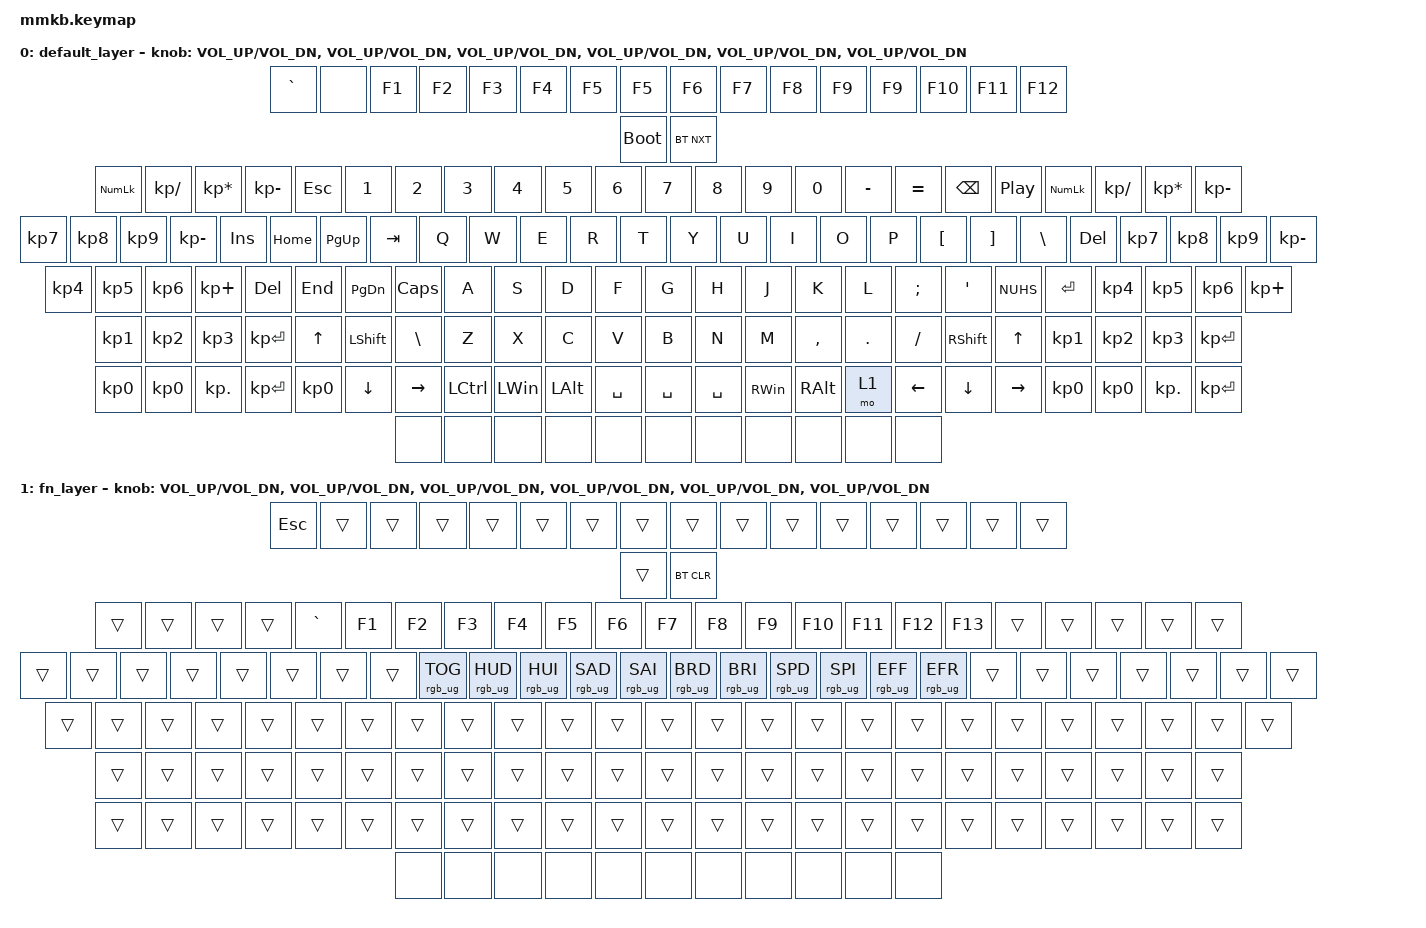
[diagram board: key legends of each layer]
/*
 * copyright (c) 2024 ZMK project contributors
 *
 * SPDX-license-identifier: MIT
 */

#include <behaviors.dtsi>
#include <dt-bindings/zmk/keys.h>
#include <dt-bindings/zmk/bt.h>
#include <dt-bindings/zmk/rgb.h>
#include <dt-bindings/zmk/outputs.h>

// uncomment exactly one layout to use
#define STANDARD           TRUE
// #define STANDARD_F13       TRUE
// #define NAV_KEYS           TRUE
// #define NAV_KEYS_F13       TRUE
// #define FLIPPED_NUMPAD     TRUE
// #define FLIPPED_NUMPAD_F13 TRUE

/ {
    keymap {
        compatible = "zmk,keymap";

        #ifdef STANDARD
        default_layer {
            /*********************************************************************************************************************************************************************************************************************************************************************************************************************************
             * STANDARD LAYOUT (DEFAULT)                                                                                                                                                                                                                                                                                                     *
             * NOTE 1: all the options in the keymap graphic show below are available purely in hardware, with no need to change the keymap (* with some exceptions), just solder the switches to their corresponding mounting point                                                                                                         *
             * NOTE 2: the character / keycode in the middle of the key is the normal binding when pressing it down, the one on the top is for when you hold "SHIFT", and the one on the bottom is when you hold "FN"                                                                                                                        *
             *                                                                                                                                                                                                                                                                                                                               *
             *                                                                                                              *********               *********               *********               *********               *********               *********                                                                                *
             *                                                                                                              * ROTARY*               * ROTARY*               * ROTARY*               * ROTARY*               * ROTARY*               * ROTARY*                                                                                *
             *                                                                                                              *ENCODER*               *ENCODER*               *ENCODER*               *ENCODER*               *ENCODER*               *ENCODER*                                                                                *
             *                                                                                                              *********               *********               *********               *********               *********               *********                                                                                *
             *                                                                                                                                                                                                                                                                                                                               *
             *                                                                                                              *********   *********************************   *********************************   *********************************   *********                                                                                *
             *                                                                                                              *   ~   *   *       *       *       *       *   *       *       *       *       *   *       *       *       *       *   *       *                                                                                *
             *                                                                                                              *   `   *   *  F1   *  F2   *  F3   *  F4   *   *  F5   *  F5   *  F6   *  F7   *   *  F9   *   F9  *  F10  *  F11  *   *  F12  *                                                                                *
             *                                                                                                              ***ESC***   *********************************   *********************************   *********************************   *********                                                                                *
             *                                                                                                               _______         _______________________________         _______________________________         _______________________________                                                                                 *
             *                                                                                                              |   ~   |       |       |       |       |       |       |       |       |       |       |       |       |       |       |       |                                                                                *
             *                                                                                                              |   `   |       |  F1   |  F2   |  F3   |  F4   |       |  F5   |  F6   |  F7   |  F8   |       |  F9   |  F10  |  F11  |  F12  |                                                                                *
             *                                                                                                              |__ESC__|       |_______|_______|_______|_______|       |_______|_______|_______|_______|       |_______|_______|_______|_______|                                                                                *
             *                                                                                                                                                                                                                                                                                                                               *
             *                                                                                                                                                                                                                      *************************                                                                                *
             *                                                                                                                                                                                                                      *   | 1U*BACK 1U* ROTARY*                                                                                *
             *            *********************************                                                                                                                                                                         *   \   *SPACE  *ENCODER*                                   *********************************            *
             *            * ROTARY* ROTARY* ROTARY* ROTARY*                                                                                                                                                                         *************************                                   * ROTARY* ROTARY* ROTARY* ROTARY*            *
             *            *ENCODER*ENCODER*ENCODER*ENCODER*                                                                                                                                                                          _______________________                                    *ENCODER*ENCODER*ENCODER*ENCODER*            *
             *            *********************************                                                                                                                                                                         | FLASH |BT_NEXT| POWER |                                   *********************************            *
             *             _______________________________                                                                   _______________________________________________________________________________________________________|_______|BT_CLR_|_______|                                    _______________________________             *
             *            |  NUM  |       |       |       |                                                                 |       |   !   |   @   |   #   |   $   |   %   |   ^   |   &   |   *   |   (   |   )   |   _   |   +   |               |       |                                   |  NUM  |       |       |       |            *
             *            |  LOCK |   \   |   *   |   -   |                                                                 |  ESC  |   1   |   2   |   3   |   4   |   5   |   6   |   7   |   8   |   9   |   0   |   -   |   =   |   BACKSPACE   |  PLAY |                                   |  LOCK |   \   |   *   |   -   |            *
             *  ********* |_______|_______|_______|_______| *********      _______________________                          |___`___|___F1__|___F2__|___F3__|___F4__|___F5__|___F6__|___F7__|___F8__|___F9__|__F10__|__F11__|__F12__|______F13______|_______|       *************     ********* |_______|_______|_______|_______| *********  *
             *  *     2U* |       |       |       |       | *     1U*     |       |       |       |                         |           |       |       |       |       |       |       |       |       |       |       |   {   |   }   |     |     |       |       *        ISO*     *     2U* |       |       |       |       | *     1U*  *
             *  *       * |   7   |   8   |   9   |       | *   -   *     |  INS  |  HOME | PG UP |                         |    TAB    |   Q   |   W   |   E   |   R   |   T   |   Y   |   U   |   I   |   O   |   P   |   [   |   ]   |     \     |  DEL  |       *           *     *       * |   7   |   8   |   9   |       | *   -   *  *
             *  *   4   * |_______|_______|_______|   +   | *********     |_______|_______|_______|         *************** |___________|RGB_TOG|RGB_HUD|RGB_HUI|RGB_SAD|RGB_SAI|RGB_BRD|RGB_BRI|RGB_SPD|RGB_SPI|RGB_EFF|RGB_EFR|_______|___________|_______| *********  ENTER  *     *   4   * |_______|_______|_______|   +   | *********  *
             *  *       * |       |       |       |       | *     1U*     |       |       |       |         *STEPPED 1.75U* |             |       |       |       |       |       |       |       |       |       |   :   |   "   |                 |       | *   | 1U*         *     *       * |       |       |       |       | *     1U*  *
             *  *       * |   4   |   5   |   6   |       | *   +   *     |  DEL  |  END  | PG DN |         *CAPS LOCK    * |  CAPS LOCK  |   A   |   S   |   D   |   F   |   G   |   H   |   J   |   K   |   L   |   ;   |   '   |      ENTER      |       | *   \   *         *     *       * |   4   |   5   |   6   |       | *   +   *  *
             *  ********* |_______|_______|_______|_______| *********     |_______|_______|_______|     ******************* |_____________|_______|_______|_______|_______|_______|_______|_______|_______|_______|_______|_______|_________________|DISPLAY| *******************     ********* |_______|_______|_______|_______| *********  *
             *  *     2U* |       |       |       |       | *     1U*             |       |             *    1.25U*   | 1U* |                 |       |       |       |       |       |       |       |   <   |   >   |   ?   |             |       |       |                         *     2U* |       |       |       |       | *     1U*  *
             *  *       * |   1   |   2   |   3   |       | * ENTER *             |  UP   |             * L SHIFT *   \   * |     L SHIFT     |   Z   |   X   |   C   |   V   |   B   |   N   |   M   |   ,   |   .   |   /   |   R SHIFT   |  UP   |       |                         *       * |   1   |   2   |   3   |       | * ENTER *  *
             *  *   0   * |_______|_______|_______| ENTER | *********      _______|_______|_______      ******************* |_________________|_______|_______|_______|_______|_______|_______|_______|_______|_______|_______|_____________|_______|_______|                         *   0   * |_______|_______|_______| ENTER | *********  *
             *  *       * |               |       |       | *     1U*     |       |       |       |                         |         |         |         |                                                 |         |         |   |       |       |       |                         *       * |               |       |       | *     1U*  *
             *  *       * |       0       |   .   |       | * ENTER *     |   0   |  DOWN | RIGHT |                         |  L CTRL |  L WIN  |  L ALT  |                                                 |  R ALT  |   FN    |   |  LEFT |  DOWN | RIGHT |                         *       * |       0       |   .   |       | * ENTER *  *
             *  ********* |_______________|_______|_______| *********     |_______|_______|_______|                         |_________|_________|_________|_________________________________________________|_________|_________|   |_______|_______|_______|                         ********* |_______________|_______|_______| *********  *
             *                                                                                                                                                                                                                                                                                                                               *
             *            *********************************                                                                                                                                                                   ***********************                                           *********************************            *
             *            *     1U*     1U*             2U*                                                                                                                                                                   *                2.75U*                                           *     1U*     1U*             2U*            *
             *            *   0   *   0   *     RIGHT     *                                                                                                                                                                   *       R SHIFT       *                                           *   0   *   0   *     RIGHT     *            *
             *            *********************************                                                                 *************************************************************************************************************************                                           *********************************            *
             *                                                                                                              *       1.5U*     1U*       1.5U*                                                     7U*       1.5U*     1U*       1.5U*                                                                                        *
             *                                                                                                              *  L CTRL   * L WIN *   L ALT   *                                                       *   R ALT   * R WIN *  R CTRL   *                                                                                        *
             *                                                                                                              *************************************************************************************************************************                                                                                        *
             *                                                                                                                                                                                                                                                                                                                               *
             *                                                                                                                                            ***************************************************                                                                                                                                *
             *                                                                                                                                            *                2.75U*            2.25U*    1.25U*                                                                                                                                *
             *                                                                                                                                            *                     *                 *  R WIN  *                                                                                                                                *
             *                                                                                                                                            ***************************************************                                                                                                                                *
             *                                                                                                                                                                                                                                                                                                                               *
             *********************************************************************************************************************************************************************************************************************************************************************************************************************************/
            bindings = <
                                                                                                                            &kp GRAVE     &none &kp F1 &kp F2 &kp F3 &kp F4     &kp F5 &kp F5 &kp F6 &kp F7 &kp F8     &kp F9 &kp F9 &kp F10 &kp F11 &kp F12
                                                                                                        
                                                                                                                                                                                                                            &bootloader &bt BT_NXT
                &kp KP_NLCK &kp KP_SLASH &kp KP_MULTIPLY &kp KP_MINUS                                                       &kp ESC &kp N1  &kp N2  &kp N3  &kp N4  &kp N5  &kp N6  &kp N7  &kp N8  &kp N9  &kp N0  &kp MINUS  &kp EQUAL   &kp BSPC  &kp C_PP                         &kp KP_NLCK &kp KP_SLASH &kp KP_MULTIPLY &kp KP_MINUS
                &kp KP_N7   &kp KP_N8    &kp KP_N9       &kp KP_MINUS    &kp INS   &kp HOME &kp PG_UP                       &kp TAB     &kp Q   &kp W   &kp E   &kp R   &kp T   &kp Y   &kp U   &kp I   &kp O   &kp P   &kp LBKT &kp RBKT   &kp BSLH  &kp DEL                         &kp KP_N7   &kp KP_N8    &kp KP_N9       &kp KP_MINUS
                &kp KP_N4   &kp KP_N5    &kp KP_N6       &kp KP_PLUS     &kp DEL   &kp END  &kp PG_DN                       &kp CAPS      &kp A   &kp S   &kp D   &kp F   &kp G   &kp H   &kp J   &kp K   &kp L  &kp SEMI &kp APOS &kp NUHS &kp ENTER                                 &kp KP_N4   &kp KP_N5    &kp KP_N6       &kp KP_PLUS
                &kp KP_N1   &kp KP_N2    &kp KP_N3       &kp KP_ENTER              &kp UP                                   &kp LSHFT &kp BSLH &kp Z  &kp X   &kp C   &kp V   &kp B   &kp N   &kp M   &kp COMMA &kp DOT &kp FSLH    &kp RSHFT  &kp UP                                 &kp KP_N1   &kp KP_N2    &kp KP_N3       &kp KP_ENTER
                &kp KP_N0   &kp KP_N0    &kp KP_DOT      &kp KP_ENTER    &kp KP_N0 &kp DOWN &kp RIGHT                       &kp LCTRL &kp LWIN  &kp LALT  &kp SPACE  &kp SPACE  &kp SPACE         &kp RWIN  &kp RALT  &mo 1       &kp LEFT &kp DOWN &kp RIGHT                         &kp KP_N0   &kp KP_N0    &kp KP_DOT      &kp KP_ENTER

                // unused virtual keys (no mounting points / footprints / traces on board)
                &none &none &none &none &none &none &none &none &none &none &none
            >;

            sensor-bindings = <&inc_dec_kp C_VOL_UP C_VOL_DN &inc_dec_kp C_VOL_UP C_VOL_DN &inc_dec_kp C_VOL_UP C_VOL_DN &inc_dec_kp C_VOL_UP C_VOL_DN &inc_dec_kp C_VOL_UP C_VOL_DN &inc_dec_kp C_VOL_UP C_VOL_DN>;
        };

        fn_layer {
            bindings = <
                                                                                                                            &kp ESC      &trans &trans &trans &trans &trans      &trans &trans &trans &trans &trans      &trans &trans &trans &trans &trans
                                                                                                        
                                                                                                                                                                                                                            &trans      &bt BT_CLR
                &trans      &trans       &trans          &trans                                                             &kp GRAVE &kp F1  &kp F2  &kp F3  &kp F4  &kp F5  &kp F6  &kp F7  &kp F8  &kp F9  &kp F10 &kp F11    &kp F12     &kp F13   &trans                                                                           &trans      &trans       &trans          &trans
                &trans      &trans       &trans          &trans          &trans    &trans   &trans                          &trans &rgb_ug RGB_TOG &rgb_ug RGB_HUD &rgb_ug RGB_HUI &rgb_ug RGB_SAD &rgb_ug RGB_SAI &rgb_ug RGB_BRD &rgb_ug RGB_BRI &rgb_ug RGB_SPD &rgb_ug RGB_SPI &rgb_ug RGB_EFF &rgb_ug RGB_EFR &trans &trans &trans &trans      &trans       &trans          &trans
                &trans      &trans       &trans          &trans          &trans    &trans   &trans                          &trans        &trans  &trans  &trans  &trans  &trans  &trans  &trans  &trans  &trans &trans   &trans   &trans   &trans                                                                                      &trans      &trans       &trans          &trans
                &trans      &trans       &trans          &trans                    &trans                                   &trans    &trans   &trans &trans  &trans  &trans  &trans  &trans  &trans  &trans    &trans  &trans      &trans     &trans                                                                                   &trans      &trans       &trans          &trans
                &trans      &trans       &trans          &trans          &trans    &trans   &trans                          &trans   &trans     &trans    &trans     &trans     &trans            &trans    &trans    &trans      &trans  &trans    &trans                                                                              &trans      &trans       &trans          &trans
                
                // unused virtual keys (no mounting points / footprints / traces on board)
                &none &none &none &none &none &none &none &none &none &none &none
            >;

            sensor-bindings = <&inc_dec_kp C_VOL_UP C_VOL_DN &inc_dec_kp C_VOL_UP C_VOL_DN &inc_dec_kp C_VOL_UP C_VOL_DN &inc_dec_kp C_VOL_UP C_VOL_DN &inc_dec_kp C_VOL_UP C_VOL_DN &inc_dec_kp C_VOL_UP C_VOL_DN>;
        };

        #elif defined(STANDARD_F13)
        default_layer {
            /*********************************************************************************************************************************************************************************************************************************************************************************************************************************
             * STANDARD + F13 LAYOUT                                                                                                                                                                                                                                                                                                         *
             * NOTE 1: all the options in the keymap graphic show below are available purely in hardware, with no need to change the keymap (* with some exceptions), just solder the switches to their corresponding mounting point                                                                                                         *
             * NOTE 2: the character / keycode in the middle of the key is the normal binding when pressing it down, the one on the top is for when you hold "SHIFT", and the one on the bottom is when you hold "FN"                                                                                                                        *
             *                                                                                                                                                                                                                                                                                                                               *
             *                                                                                                              *********               *********               *********               *********               *********               *********                                                                                *
             *                                                                                                              * ROTARY*               * ROTARY*               * ROTARY*               * ROTARY*               * ROTARY*               * ROTARY*                                                                                *
             *                                                                                                              *ENCODER*               *ENCODER*               *ENCODER*               *ENCODER*               *ENCODER*               *ENCODER*                                                                                *
             *                                                                                                              *********               *********               *********               *********               *********               *********                                                                                *
             *                                                                                                                                                                                                                                                                                                                               *
             *                                                                                                              *********   *********************************   *********************************   *********************************   *********                                                                                *
             *                                                                                                              *   ~   *   *       *       *       *       *   *       *       *       *       *   *       *       *       *       *   *       *                                                                                *
             *                                                                                                              *   `   *   *  F1   *  F2   *  F3   *  F4   *   *  F5   *  F6   *  F7   *  F8   *   *  F9   *  F10  *  F11  *  F12  *   *  F13  *                                                                                *
             *                                                                                                              ***ESC***   *********************************   *********************************   *********************************   *********                                                                                *
             *                                                                                                               _______         _______________________________         _______________________________         _______________________________                                                                                 *
             *                                                                                                              |   ~   |       |       |       |       |       |       |       |       |       |       |       |       |       |       |       |                                                                                *
             *                                                                                                              |   `   |       |  F1   |  F2   |  F3   |  F4   |       |  F6   |  F7   |  F8   |  F8   |       |  F10  |  F11  |  F12  |  F13  |                                                                                *
             *                                                                                                              |__ESC__|       |_______|_______|_______|_______|       |_______|_______|_______|_______|       |_______|_______|_______|_______|                                                                                *
             *                                                                                                                                                                                                                                                                                                                               *
             *                                                                                                                                                                                                                      *************************                                                                                *
             *                                                                                                                                                                                                                      *   | 1U*BACK 1U* ROTARY*                                                                                *
             *            *********************************                                                                                                                                                                         *   \   *SPACE  *ENCODER*                                   *********************************            *
             *            * ROTARY* ROTARY* ROTARY* ROTARY*                                                                                                                                                                         *************************                                   * ROTARY* ROTARY* ROTARY* ROTARY*            *
             *            *ENCODER*ENCODER*ENCODER*ENCODER*                                                                                                                                                                          _______________________                                    *ENCODER*ENCODER*ENCODER*ENCODER*            *
             *            *********************************                                                                                                                                                                         | FLASH |BT_NEXT| POWER |                                   *********************************            *
             *             _______________________________                                                                   _______________________________________________________________________________________________________|_______|BT_CLR_|_______|                                    _______________________________             *
             *            |  NUM  |       |       |       |                                                                 |       |   !   |   @   |   #   |   $   |   %   |   ^   |   &   |   *   |   (   |   )   |   _   |   +   |               |       |                                   |  NUM  |       |       |       |            *
             *            |  LOCK |   \   |   *   |   -   |                                                                 |  ESC  |   1   |   2   |   3   |   4   |   5   |   6   |   7   |   8   |   9   |   0   |   -   |   =   |   BACKSPACE   |  PLAY |                                   |  LOCK |   \   |   *   |   -   |            *
             *  ********* |_______|_______|_______|_______| *********      _______________________                          |___`___|___F1__|___F2__|___F3__|___F4__|___F5__|___F6__|___F7__|___F8__|___F9__|__F10__|__F11__|__F12__|______F13______|_______|       *************     ********* |_______|_______|_______|_______| *********  *
             *  *     2U* |       |       |       |       | *     1U*     |       |       |       |                         |           |       |       |       |       |       |       |       |       |       |       |   {   |   }   |     |     |       |       *        ISO*     *     2U* |       |       |       |       | *     1U*  *
             *  *       * |   7   |   8   |   9   |       | *   -   *     |  INS  |  HOME | PG UP |                         |    TAB    |   Q   |   W   |   E   |   R   |   T   |   Y   |   U   |   I   |   O   |   P   |   [   |   ]   |     \     |  DEL  |       *           *     *       * |   7   |   8   |   9   |       | *   -   *  *
             *  *   4   * |_______|_______|_______|   +   | *********     |_______|_______|_______|         *************** |___________|RGB_TOG|RGB_HUD|RGB_HUI|RGB_SAD|RGB_SAI|RGB_BRD|RGB_BRI|RGB_SPD|RGB_SPI|RGB_EFF|RGB_EFR|_______|___________|_______| *********  ENTER  *     *   4   * |_______|_______|_______|   +   | *********  *
             *  *       * |       |       |       |       | *     1U*     |       |       |       |         *STEPPED 1.75U* |             |       |       |       |       |       |       |       |       |       |   :   |   "   |                 |       | *   | 1U*         *     *       * |       |       |       |       | *     1U*  *
             *  *       * |   4   |   5   |   6   |       | *   +   *     |  DEL  |  END  | PG DN |         *CAPS LOCK    * |  CAPS LOCK  |   A   |   S   |   D   |   F   |   G   |   H   |   J   |   K   |   L   |   ;   |   '   |      ENTER      |       | *   \   *         *     *       * |   4   |   5   |   6   |       | *   +   *  *
             *  ********* |_______|_______|_______|_______| *********     |_______|_______|_______|     ******************* |_____________|_______|_______|_______|_______|_______|_______|_______|_______|_______|_______|_______|_________________|DISPLAY| *******************     ********* |_______|_______|_______|_______| *********  *
             *  *     2U* |       |       |       |       | *     1U*             |       |             *    1.25U*   | 1U* |                 |       |       |       |       |       |       |       |   <   |   >   |   ?   |             |       |       |                         *     2U* |       |       |       |       | *     1U*  *
             *  *       * |   1   |   2   |   3   |       | * ENTER *             |  UP   |             * L SHIFT *   \   * |     L SHIFT     |   Z   |   X   |   C   |   V   |   B   |   N   |   M   |   ,   |   .   |   /   |   R SHIFT   |  UP   |       |                         *       * |   1   |   2   |   3   |       | * ENTER *  *
             *  *   0   * |_______|_______|_______| ENTER | *********      _______|_______|_______      ******************* |_________________|_______|_______|_______|_______|_______|_______|_______|_______|_______|_______|_____________|_______|_______|                         *   0   * |_______|_______|_______| ENTER | *********  *
             *  *       * |               |       |       | *     1U*     |       |       |       |                         |         |         |         |                                                 |         |         |   |       |       |       |                         *       * |               |       |       | *     1U*  *
             *  *       * |       0       |   .   |       | * ENTER *     |   0   |  DOWN | RIGHT |                         |  L CTRL |  L WIN  |  L ALT  |                                                 |  R ALT  |   FN    |   |  LEFT |  DOWN | RIGHT |                         *       * |       0       |   .   |       | * ENTER *  *
             *  ********* |_______________|_______|_______| *********     |_______|_______|_______|                         |_________|_________|_________|_________________________________________________|_________|_________|   |_______|_______|_______|                         ********* |_______________|_______|_______| *********  *
             *                                                                                                                                                                                                                                                                                                                               *
             *            *********************************                                                                                                                                                                   ***********************                                           *********************************            *
             *            *     1U*     1U*             2U*                                                                                                                                                                   *                2.75U*                                           *     1U*     1U*             2U*            *
             *            *   0   *   0   *     RIGHT     *                                                                                                                                                                   *       R SHIFT       *                                           *   0   *   0   *     RIGHT     *            *
             *            *********************************                                                                 *************************************************************************************************************************                                           *********************************            *
             *                                                                                                              *       1.5U*     1U*       1.5U*                                                     7U*       1.5U*     1U*       1.5U*                                                                                        *
             *                                                                                                              *  L CTRL   * L WIN *   L ALT   *                                                       *   R ALT   * R WIN *  R CTRL   *                                                                                        *
             *                                                                                                              *************************************************************************************************************************                                                                                        *
             *                                                                                                                                                                                                                                                                                                                               *
             *                                                                                                                                            ***************************************************                                                                                                                                *
             *                                                                                                                                            *                2.75U*            2.25U*    1.25U*                                                                                                                                *
             *                                                                                                                                            *                     *                 *  R WIN  *                                                                                                                                *
             *                                                                                                                                            ***************************************************                                                                                                                                *
             *                                                                                                                                                                                                                                                                                                                               *
             *********************************************************************************************************************************************************************************************************************************************************************************************************************************/
            bindings = <
                                                                                                                            &kp GRAVE     &none &kp F1 &kp F2 &kp F3 &kp F4     &kp F5 &kp F6 &kp F7 &kp F8 &kp F8     &kp F9 &kp F10 &kp F11 &kp F12 &kp F13
                                                                                                        
                                                                                                                                                                                                                            &bootloader &bt BT_NXT
                &kp KP_NLCK &kp KP_SLASH &kp KP_MULTIPLY &kp KP_MINUS                                                       &kp ESC &kp N1  &kp N2  &kp N3  &kp N4  &kp N5  &kp N6  &kp N7  &kp N8  &kp N9  &kp N0  &kp MINUS  &kp EQUAL   &kp BSPC  &kp C_PP                         &kp KP_NLCK &kp KP_SLASH &kp KP_MULTIPLY &kp KP_MINUS
                &kp KP_N7   &kp KP_N8    &kp KP_N9       &kp KP_MINUS    &kp INS   &kp HOME &kp PG_UP                       &kp TAB     &kp Q   &kp W   &kp E   &kp R   &kp T   &kp Y   &kp U   &kp I   &kp O   &kp P   &kp LBKT &kp RBKT   &kp BSLH  &kp DEL                         &kp KP_N7   &kp KP_N8    &kp KP_N9       &kp KP_MINUS
                &kp KP_N4   &kp KP_N5    &kp KP_N6       &kp KP_PLUS     &kp DEL   &kp END  &kp PG_DN                       &kp CAPS      &kp A   &kp S   &kp D   &kp F   &kp G   &kp H   &kp J   &kp K   &kp L  &kp SEMI &kp APOS &kp NUHS &kp ENTER                                 &kp KP_N4   &kp KP_N5    &kp KP_N6       &kp KP_PLUS
                &kp KP_N1   &kp KP_N2    &kp KP_N3       &kp KP_ENTER              &kp UP                                   &kp LSHFT &kp BSLH &kp Z  &kp X   &kp C   &kp V   &kp B   &kp N   &kp M   &kp COMMA &kp DOT &kp FSLH    &kp RSHFT  &kp UP                                 &kp KP_N1   &kp KP_N2    &kp KP_N3       &kp KP_ENTER
                &kp KP_N0   &kp KP_N0    &kp KP_DOT      &kp KP_ENTER    &kp KP_N0 &kp DOWN &kp RIGHT                       &kp LCTRL &kp LWIN  &kp LALT  &kp SPACE  &kp SPACE  &kp SPACE         &kp RWIN  &kp RALT  &mo 1       &kp LEFT &kp DOWN &kp RIGHT                         &kp KP_N0   &kp KP_N0    &kp KP_DOT      &kp KP_ENTER

                // unused virtual keys (no mounting points / footprints / traces on board)
                &none &none &none &none &none &none &none &none &none &none &none
            >;

            sensor-bindings = <&inc_dec_kp C_VOL_UP C_VOL_DN &inc_dec_kp C_VOL_UP C_VOL_DN &inc_dec_kp C_VOL_UP C_VOL_DN &inc_dec_kp C_VOL_UP C_VOL_DN &inc_dec_kp C_VOL_UP C_VOL_DN &inc_dec_kp C_VOL_UP C_VOL_DN>;
        };

        fn_layer {
            bindings = <
                                                                                                                            &kp ESC      &trans &trans &trans &trans &trans      &trans &trans &trans &trans &trans      &trans &trans &trans &trans &trans
                                                                                                        
                                                                                                                                                                                                                            &trans      &bt BT_CLR
                &trans      &trans       &trans          &trans                                                             &kp GRAVE &kp F1  &kp F2  &kp F3  &kp F4  &kp F5  &kp F6  &kp F7  &kp F8  &kp F9  &kp F10 &kp F11    &kp F12     &kp F13   &trans                                                                           &trans      &trans       &trans          &trans
                &trans      &trans       &trans          &trans          &trans    &trans   &trans                          &trans &rgb_ug RGB_TOG &rgb_ug RGB_HUD &rgb_ug RGB_HUI &rgb_ug RGB_SAD &rgb_ug RGB_SAI &rgb_ug RGB_BRD &rgb_ug RGB_BRI &rgb_ug RGB_SPD &rgb_ug RGB_SPI &rgb_ug RGB_EFF &rgb_ug RGB_EFR &trans &trans &trans &trans      &trans       &trans          &trans
                &trans      &trans       &trans          &trans          &trans    &trans   &trans                          &trans        &trans  &trans  &trans  &trans  &trans  &trans  &trans  &trans  &trans &trans   &trans   &trans   &trans                                                                                      &trans      &trans       &trans          &trans
                &trans      &trans       &trans          &trans                    &trans                                   &trans    &trans   &trans &trans  &trans  &trans  &trans  &trans  &trans  &trans    &trans  &trans      &trans     &trans                                                                                   &trans      &trans       &trans          &trans
                &trans      &trans       &trans          &trans          &trans    &trans   &trans                          &trans   &trans     &trans    &trans     &trans     &trans            &trans    &trans    &trans      &trans  &trans    &trans                                                                              &trans      &trans       &trans          &trans
                
                // unused virtual keys (no mounting points / footprints / traces on board)
                &none &none &none &none &none &none &none &none &none &none &none
            >;

            sensor-bindings = <&inc_dec_kp C_VOL_UP C_VOL_DN &inc_dec_kp C_VOL_UP C_VOL_DN &inc_dec_kp C_VOL_UP C_VOL_DN &inc_dec_kp C_VOL_UP C_VOL_DN &inc_dec_kp C_VOL_UP C_VOL_DN &inc_dec_kp C_VOL_UP C_VOL_DN>;
        };
        
        // due to a hardware layout oversight, if you want the left arrow on the navigation keys on the side module to work properly, you need to use this binding
        #elif defined(NAV_KEYS)
        default_layer {
            /*********************************************************************************************************************************************************************************************************************************************************************************************************************************
             * NAVIGATION KEYS LAYOUT                                                                                                                                                                                                                                                                                                        *
             * NOTE 1: all the options in the keymap graphic show below are available purely in hardware, with no need to change the keymap (* with some exceptions), just solder the switches to their corresponding mounting point                                                                                                         *
             * NOTE 2: the character / keycode in the middle of the key is the normal binding when pressing it down, the one on the top is for when you hold "SHIFT", and the one on the bottom is when you hold "FN"                                                                                                                        *
             *                                                                                                                                                                                                                                                                                                                               *
             *                                                                                                              *********               *********               *********               *********               *********               *********                                                                                *
             *                                                                                                              * ROTARY*               * ROTARY*               * ROTARY*               * ROTARY*               * ROTARY*               * ROTARY*                                                                                *
             *                                                                                                              *ENCODER*               *ENCODER*               *ENCODER*               *ENCODER*               *ENCODER*               *ENCODER*                                                                                *
             *                                                                                                              *********               *********               *********               *********               *********               *********                                                                                *
             *                                                                                                                                                                                                                                                                                                                               *
             *                                                                                                              *********   *********************************   *********************************   *********************************   *********                                                                                *
             *                                                                                                              *   ~   *   *       *       *       *       *   *       *       *       *       *   *       *       *       *       *   *       *                                                                                *
             *                                                                                                              *   `   *   *  F1   *  F2   *  F3   *  F4   *   *  F5   *  F5   *  F6   *  F7   *   *  F9   *   F9  *  F10  *  F11  *   *  F12  *                                                                                *
             *                                                                                                              ***ESC***   *********************************   *********************************   *********************************   *********                                                                                *
             *                                                                                                               _______         _______________________________         _______________________________         _______________________________                                                                                 *
             *                                                                                                              |   ~   |       |       |       |       |       |       |       |       |       |       |       |       |       |       |       |                                                                                *
             *                                                                                                              |   `   |       |  F1   |  F2   |  F3   |  F4   |       |  F5   |  F6   |  F7   |  F8   |       |  F9   |  F10  |  F11  |  F12  |                                                                                *
             *                                                                                                              |__ESC__|       |_______|_______|_______|_______|       |_______|_______|_______|_______|       |_______|_______|_______|_______|                                                                                *
             *                                                                                                                                                                                                                                                                                                                               *
             *                                                                                                                                                                                                                      *************************                                                                                *
             *                                                                                                                                                                                                                      *   | 1U*BACK 1U* ROTARY*                                                                                *
             *            *********************************                                                                                                                                                                         *   \   *SPACE  *ENCODER*                                   *********************************            *
             *            * ROTARY* ROTARY* ROTARY* ROTARY*                                                                                                                                                                         *************************                                   * ROTARY* ROTARY* ROTARY* ROTARY*            *
             *            *ENCODER*ENCODER*ENCODER*ENCODER*                                                                                                                                                                          _______________________                                    *ENCODER*ENCODER*ENCODER*ENCODER*            *
             *            *********************************                                                                                                                                                                         | FLASH |BT_NEXT| POWER |                                   *********************************            *
             *             _______________________________                                                                   _______________________________________________________________________________________________________|_______|BT_CLR_|_______|                                    _______________________________             *
             *            |  NUM  |       |       |       |                                                                 |       |   !   |   @   |   #   |   $   |   %   |   ^   |   &   |   *   |   (   |   )   |   _   |   +   |               |       |                                   |  NUM  |       |       |       |            *
             *            |  LOCK |   \   |   *   |   -   |                                                                 |  ESC  |   1   |   2   |   3   |   4   |   5   |   6   |   7   |   8   |   9   |   0   |   -   |   =   |   BACKSPACE   |  PLAY |                                   |  LOCK |   \   |   *   |   -   |            *
             *  ********* |_______|_______|_______|_______| *********      _______________________                          |___`___|___F1__|___F2__|___F3__|___F4__|___F5__|___F6__|___F7__|___F8__|___F9__|__F10__|__F11__|__F12__|______F13______|_______|       *************     ********* |_______|_______|_______|_______| *********  *
             *  *     2U* |       |       |       |       | *     1U*     |       |       |       |                         |           |       |       |       |       |       |       |       |       |       |       |   {   |   }   |     |     |       |       *        ISO*     *     2U* |       |       |       |       | *     1U*  *
             *  *       * |   7   |   8   |   9   |       | *   -   *     |  INS  |  HOME | PG UP |                         |    TAB    |   Q   |   W   |   E   |   R   |   T   |   Y   |   U   |   I   |   O   |   P   |   [   |   ]   |     \     |  DEL  |       *           *     *       * |   7   |   8   |   9   |       | *   -   *  *
             *  *   4   * |_______|_______|_______|   +   | *********     |_______|_______|_______|         *************** |___________|RGB_TOG|RGB_HUD|RGB_HUI|RGB_SAD|RGB_SAI|RGB_BRD|RGB_BRI|RGB_SPD|RGB_SPI|RGB_EFF|RGB_EFR|_______|___________|_______| *********  ENTER  *     *   4   * |_______|_______|_______|   +   | *********  *
             *  *       * |       |       |       |       | *     1U*     |       |       |       |         *STEPPED 1.75U* |             |       |       |       |       |       |       |       |       |       |   :   |   "   |                 |       | *   | 1U*         *     *       * |       |       |       |       | *     1U*  *
             *  *       * |   4   |   5   |   6   |       | *   +   *     |  DEL  |  END  | PG DN |         *CAPS LOCK    * |  CAPS LOCK  |   A   |   S   |   D   |   F   |   G   |   H   |   J   |   K   |   L   |   ;   |   '   |      ENTER      |       | *   \   *         *     *       * |   4   |   5   |   6   |       | *   +   *  *
             *  ********* |_______|_______|_______|_______| *********     |_______|_______|_______|     ******************* |_____________|_______|_______|_______|_______|_______|_______|_______|_______|_______|_______|_______|_________________|DISPLAY| *******************     ********* |_______|_______|_______|_______| *********  *
             *  *     2U* |       |       |       |       | *     1U*             |       |             *    1.25U*   | 1U* |                 |       |       |       |       |       |       |       |   <   |   >   |   ?   |             |       |       |                         *     2U* |       |       |       |       | *     1U*  *
             *  *       * |   1   |   2   |   3   |       | * ENTER *             |  UP   |             * L SHIFT *   \   * |     L SHIFT     |   Z   |   X   |   C   |   V   |   B   |   N   |   M   |   ,   |   .   |   /   |   R SHIFT   |  UP   |       |                         *       * |   1   |   2   |   3   |       | * RIGHT *  *
             *  *   0   * |_______|_______|_______| ENTER | *********      _______|_______|_______      ******************* |_________________|_______|_______|_______|_______|_______|_______|_______|_______|_______|_______|_____________|_______|_______|                         *   0   * |_______|_______|_______| ENTER | *********  *
             *  *       * |               |       |       | *     1U*     |       |       |       |                         |         |         |         |                                                 |         |         |   |       |       |       |                         *       * |               |       |       | *     1U*  *
             *  *       * |      LEFT     |   .   |       | * ENTER *     |  LEFT |  DOWN | RIGHT |                         |  L CTRL |  L WIN  |  L ALT  |                                                 |  R ALT  |   FN    |   |  LEFT |  DOWN | RIGHT |                         *       * |      LEFT     |   .   |       | * RIGHT *  *
             *  ********* |_______________|_______|_______| *********     |_______|_______|_______|                         |_________|_________|_________|_________________________________________________|_________|_________|   |_______|_______|_______|                         ********* |_______________|_______|_______| *********  *
             *                                                                                                                                                                                                                                                                                                                               *
             *            *********************************                                                                                                                                                                   ***********************                                           *********************************            *
             *            *     1U*     1U*             2U*                                                                                                                                                                   *                2.75U*                                           *     1U*     1U*             2U*            *
             *            *   0   *   0   *     RIGHT     *                                                                                                                                                                   *       R SHIFT       *                                           *   0   *   0   *     RIGHT     *            *
             *            *********************************                                                                 *************************************************************************************************************************                                           *********************************            *
             *                                                                                                              *       1.5U*     1U*       1.5U*                                                     7U*       1.5U*     1U*       1.5U*                                                                                        *
             *                                                                                                              *  L CTRL   * L WIN *   L ALT   *                                                       *   R ALT   * R WIN *  R CTRL   *                                                                                        *
             *                                                                                                              *************************************************************************************************************************                                                                                        *
             *                                                                                                                                                                                                                                                                                                                               *
             *                                                                                                                                            ***************************************************                                                                                                                                *
             *                                                                                                                                            *                2.75U*            2.25U*    1.25U*                                                                                                                                *
             *                                                                                                                                            *                     *                 *  R WIN  *                                                                                                                                *
             *                                                                                                                                            ***************************************************                                                                                                                                *
             *                                                                                                                                                                                                                                                                                                                               *
             *********************************************************************************************************************************************************************************************************************************************************************************************************************************/
            bindings = <
                                                                                                                            &kp GRAVE     &none &kp F1 &kp F2 &kp F3 &kp F4     &kp F5 &kp F5 &kp F6 &kp F7 &kp F8     &kp F9 &kp F9 &kp F10 &kp F11 &kp F12
                                                                                                        
                                                                                                                                                                                                                            &bootloader &bt BT_NXT
                &kp KP_NLCK &kp KP_SLASH &kp KP_MULTIPLY &kp KP_MINUS                                                       &kp ESC &kp N1  &kp N2  &kp N3  &kp N4  &kp N5  &kp N6  &kp N7  &kp N8  &kp N9  &kp N0  &kp MINUS  &kp EQUAL   &kp BSPC  &kp C_PP                         &kp KP_NLCK &kp KP_SLASH &kp KP_MULTIPLY &kp KP_MINUS
                &kp KP_N7   &kp KP_N8    &kp KP_N9       &kp KP_MINUS    &kp INS   &kp HOME &kp PG_UP                       &kp TAB     &kp Q   &kp W   &kp E   &kp R   &kp T   &kp Y   &kp U   &kp I   &kp O   &kp P   &kp LBKT &kp RBKT   &kp BSLH  &kp DEL                         &kp KP_N7   &kp KP_N8    &kp KP_N9       &kp KP_MINUS
                &kp KP_N4   &kp KP_N5    &kp KP_N6       &kp KP_PLUS     &kp DEL   &kp END  &kp PG_DN                       &kp CAPS      &kp A   &kp S   &kp D   &kp F   &kp G   &kp H   &kp J   &kp K   &kp L  &kp SEMI &kp APOS &kp NUHS &kp ENTER                                 &kp KP_N4   &kp KP_N5    &kp KP_N6       &kp KP_PLUS
                &kp KP_N1   &kp KP_N2    &kp KP_N3       &kp KP_ENTER              &kp UP                                   &kp LSHFT &kp BSLH &kp Z  &kp X   &kp C   &kp V   &kp B   &kp N   &kp M   &kp COMMA &kp DOT &kp FSLH    &kp RSHFT  &kp UP                                 &kp KP_N1   &kp KP_N2    &kp KP_N3       &kp KP_ENTER
                &kp KP_N0   &kp KP_N0    &kp KP_DOT      &kp KP_ENTER    &kp LEFT  &kp DOWN &kp RIGHT                       &kp LCTRL &kp LWIN  &kp LALT  &kp SPACE  &kp SPACE  &kp SPACE         &kp RWIN  &kp RALT  &mo 1       &kp LEFT &kp DOWN &kp RIGHT                         &kp KP_N0   &kp KP_N0    &kp KP_DOT      &kp KP_ENTER

                // unused virtual keys (no mounting points / footprints / traces on board)
                &none &none &none &none &none &none &none &none &none &none &none
            >;

            sensor-bindings = <&inc_dec_kp C_VOL_UP C_VOL_DN &inc_dec_kp C_VOL_UP C_VOL_DN &inc_dec_kp C_VOL_UP C_VOL_DN &inc_dec_kp C_VOL_UP C_VOL_DN &inc_dec_kp C_VOL_UP C_VOL_DN &inc_dec_kp C_VOL_UP C_VOL_DN>;
        };

        fn_layer {
            bindings = <
                                                                                                                            &kp ESC      &trans &trans &trans &trans &trans      &trans &trans &trans &trans &trans      &trans &trans &trans &trans &trans
                                                                                                        
                                                                                                                                                                                                                            &trans      &bt BT_CLR
                &trans      &trans       &trans          &trans                                                             &kp GRAVE &kp F1  &kp F2  &kp F3  &kp F4  &kp F5  &kp F6  &kp F7  &kp F8  &kp F9  &kp F10 &kp F11    &kp F12     &kp F13   &trans                                                                           &trans      &trans       &trans          &trans
                &trans      &trans       &trans          &trans          &trans    &trans   &trans                          &trans &rgb_ug RGB_TOG &rgb_ug RGB_HUD &rgb_ug RGB_HUI &rgb_ug RGB_SAD &rgb_ug RGB_SAI &rgb_ug RGB_BRD &rgb_ug RGB_BRI &rgb_ug RGB_SPD &rgb_ug RGB_SPI &rgb_ug RGB_EFF &rgb_ug RGB_EFR &trans &trans &trans &trans      &trans       &trans          &trans
                &trans      &trans       &trans          &trans          &trans    &trans   &trans                          &trans        &trans  &trans  &trans  &trans  &trans  &trans  &trans  &trans  &trans &trans   &trans   &trans   &trans                                                                                      &trans      &trans       &trans          &trans
                &trans      &trans       &trans          &trans                    &trans                                   &trans    &trans   &trans &trans  &trans  &trans  &trans  &trans  &trans  &trans    &trans  &trans      &trans     &trans                                                                                   &trans      &trans       &trans          &trans
                &trans      &trans       &trans          &trans          &trans    &trans   &trans                          &trans   &trans     &trans    &trans     &trans     &trans            &trans    &trans    &trans      &trans  &trans    &trans                                                                              &trans      &trans       &trans          &trans

                // unused virtual keys (no mounting points / footprints / traces on board)
                &none &none &none &none &none &none &none &none &none &none &none
            >;

            sensor-bindings = <&inc_dec_kp C_VOL_UP C_VOL_DN &inc_dec_kp C_VOL_UP C_VOL_DN &inc_dec_kp C_VOL_UP C_VOL_DN &inc_dec_kp C_VOL_UP C_VOL_DN &inc_dec_kp C_VOL_UP C_VOL_DN &inc_dec_kp C_VOL_UP C_VOL_DN>;
        };

        // due to a hardware layout oversight, if you want the left arrow on the navigation keys on the side module to work properly and an F13 layout function row, you need to use this binding
        #elif defined(NAV_KEYS_F13)
        default_layer {
            /*********************************************************************************************************************************************************************************************************************************************************************************************************************************
             * NAVIGATION KEYS + F13 LAYOUT                                                                                                                                                                                                                                                                                                  *
             * NOTE 1: all the options in the keymap graphic show below are available purely in hardware, with no need to change the keymap (* with some exceptions), just solder the switches to their corresponding mounting point                                                                                                         *
             * NOTE 2: the character / keycode in the middle of the key is the normal binding when pressing it down, the one on the top is for when you hold "SHIFT", and the one on the bottom is when you hold "FN"                                                                                                                        *
             *                                                                                                                                                                                                                                                                                                                               *
             *                                                                                                              *********               *********               *********               *********               *********               *********                                                                                *
             *                                                                                                              * ROTARY*               * ROTARY*               * ROTARY*               * ROTARY*               * ROTARY*               * ROTARY*                                                                                *
             *                                                                                                              *ENCODER*               *ENCODER*               *ENCODER*               *ENCODER*               *ENCODER*               *ENCODER*                                                                                *
             *                                                                                                              *********               *********               *********               *********               *********               *********                                                                                *
             *                                                                                                                                                                                                                                                                                                                               *
             *                                                                                                              *********   *********************************   *********************************   *********************************   *********                                                                                *
             *                                                                                                              *   ~   *   *       *       *       *       *   *       *       *       *       *   *       *       *       *       *   *       *                                                                                *
             *                                                                                                              *   `   *   *  F1   *  F2   *  F3   *  F4   *   *  F5   *  F6   *  F7   *  F8   *   *  F9   *  F10  *  F11  *  F12  *   *  F13  *                                                                                *
             *                                                                                                              ***ESC***   *********************************   *********************************   *********************************   *********                                                                                *
             *                                                                                                               _______         _______________________________         _______________________________         _______________________________                                                                                 *
             *                                                                                                              |   ~   |       |       |       |       |       |       |       |       |       |       |       |       |       |       |       |                                                                                *
             *                                                                                                              |   `   |       |  F1   |  F2   |  F3   |  F4   |       |  F6   |  F7   |  F8   |  F8   |       |  F10  |  F11  |  F12  |  F13  |                                                                                *
             *                                                                                                              |__ESC__|       |_______|_______|_______|_______|       |_______|_______|_______|_______|       |_______|_______|_______|_______|                                                                                *
             *                                                                                                                                                                                                                                                                                                                               *
             *                                                                                                                                                                                                                      *************************                                                                                *
             *                                                                                                                                                                                                                      *   | 1U*BACK 1U* ROTARY*                                                                                *
             *            *********************************                                                                                                                                                                         *   \   *SPACE  *ENCODER*                                   *********************************            *
             *            * ROTARY* ROTARY* ROTARY* ROTARY*                                                                                                                                                                         *************************                                   * ROTARY* ROTARY* ROTARY* ROTARY*            *
             *            *ENCODER*ENCODER*ENCODER*ENCODER*                                                                                                                                                                          _______________________                                    *ENCODER*ENCODER*ENCODER*ENCODER*            *
             *            *********************************                                                                                                                                                                         | FLASH |BT_NEXT| POWER |                                   *********************************            *
             *             _______________________________                                                                   _______________________________________________________________________________________________________|_______|BT_CLR_|_______|                                    _______________________________             *
             *            |  NUM  |       |       |       |                                                                 |       |   !   |   @   |   #   |   $   |   %   |   ^   |   &   |   *   |   (   |   )   |   _   |   +   |               |       |                                   |  NUM  |       |       |       |            *
             *            |  LOCK |   \   |   *   |   -   |                                                                 |  ESC  |   1   |   2   |   3   |   4   |   5   |   6   |   7   |   8   |   9   |   0   |   -   |   =   |   BACKSPACE   |  PLAY |                                   |  LOCK |   \   |   *   |   -   |            *
             *  ********* |_______|_______|_______|_______| *********      _______________________                          |___`___|___F1__|___F2__|___F3__|___F4__|___F5__|___F6__|___F7__|___F8__|___F9__|__F10__|__F11__|__F12__|______F13______|_______|       *************     ********* |_______|_______|_______|_______| *********  *
             *  *     2U* |       |       |       |       | *     1U*     |       |       |       |                         |           |       |       |       |       |       |       |       |       |       |       |   {   |   }   |     |     |       |       *        ISO*     *     2U* |       |       |       |       | *     1U*  *
             *  *       * |   7   |   8   |   9   |       | *   -   *     |  INS  |  HOME | PG UP |                         |    TAB    |   Q   |   W   |   E   |   R   |   T   |   Y   |   U   |   I   |   O   |   P   |   [   |   ]   |     \     |  DEL  |       *           *     *       * |   7   |   8   |   9   |       | *   -   *  *
             *  *   4   * |_______|_______|_______|   +   | *********     |_______|_______|_______|         *************** |___________|RGB_TOG|RGB_HUD|RGB_HUI|RGB_SAD|RGB_SAI|RGB_BRD|RGB_BRI|RGB_SPD|RGB_SPI|RGB_EFF|RGB_EFR|_______|___________|_______| *********  ENTER  *     *   4   * |_______|_______|_______|   +   | *********  *
             *  *       * |       |       |       |       | *     1U*     |       |       |       |         *STEPPED 1.75U* |             |       |       |       |       |       |       |       |       |       |   :   |   "   |                 |       | *   | 1U*         *     *       * |       |       |       |       | *     1U*  *
             *  *       * |   4   |   5   |   6   |       | *   +   *     |  DEL  |  END  | PG DN |         *CAPS LOCK    * |  CAPS LOCK  |   A   |   S   |   D   |   F   |   G   |   H   |   J   |   K   |   L   |   ;   |   '   |      ENTER      |       | *   \   *         *     *       * |   4   |   5   |   6   |       | *   +   *  *
             *  ********* |_______|_______|_______|_______| *********     |_______|_______|_______|     ******************* |_____________|_______|_______|_______|_______|_______|_______|_______|_______|_______|_______|_______|_________________|DISPLAY| *******************     ********* |_______|_______|_______|_______| *********  *
             *  *     2U* |       |       |       |       | *     1U*             |       |             *    1.25U*   | 1U* |                 |       |       |       |       |       |       |       |   <   |   >   |   ?   |             |       |       |                         *     2U* |       |       |       |       | *     1U*  *
             *  *       * |   1   |   2   |   3   |       | * ENTER *             |  UP   |             * L SHIFT *   \   * |     L SHIFT     |   Z   |   X   |   C   |   V   |   B   |   N   |   M   |   ,   |   .   |   /   |   R SHIFT   |  UP   |       |                         *       * |   1   |   2   |   3   |       | * RIGHT *  *
             *  *   0   * |_______|_______|_______| ENTER | *********      _______|_______|_______      ******************* |_________________|_______|_______|_______|_______|_______|_______|_______|_______|_______|_______|_____________|_______|_______|                         *   0   * |_______|_______|_______| ENTER | *********  *
             *  *       * |               |       |       | *     1U*     |       |       |       |                         |         |         |         |                                                 |         |         |   |       |       |       |                         *       * |               |       |       | *     1U*  *
             *  *       * |      LEFT     |   .   |       | * ENTER *     |  LEFT |  DOWN | RIGHT |                         |  L CTRL |  L WIN  |  L ALT  |                                                 |  R ALT  |   FN    |   |  LEFT |  DOWN | RIGHT |                         *       * |      LEFT     |   .   |       | * RIGHT *  *
             *  ********* |_______________|_______|_______| *********     |_______|_______|_______|                         |_________|_________|_________|_________________________________________________|_________|_________|   |_______|_______|_______|                         ********* |_______________|_______|_______| *********  *
             *                                                                                                                                                                                                                                                                                                                               *
             *            *********************************                                                                                                                                                                   ***********************                                           *********************************            *
             *            *     1U*     1U*             2U*                                                                                                                                                                   *                2.75U*                                           *     1U*     1U*             2U*            *
             *            *   0   *   0   *     RIGHT     *                                                                                                                                                                   *       R SHIFT       *                                           *   0   *   0   *     RIGHT     *            *
             *            *********************************                                                                 *************************************************************************************************************************                                           *********************************            *
             *                                                                                                              *       1.5U*     1U*       1.5U*                                                     7U*       1.5U*     1U*       1.5U*                                                                                        *
             *                                                                                                              *  L CTRL   * L WIN *   L ALT   *                                                       *   R ALT   * R WIN *  R CTRL   *                                                                                        *
             *                                                                                                              *************************************************************************************************************************                                                                                        *
             *                                                                                                                                                                                                                                                                                                                               *
             *                                                                                                                                            ***************************************************                                                                                                                                *
             *                                                                                                                                            *                2.75U*            2.25U*    1.25U*                                                                                                                                *
             *                                                                                                                                            *                     *                 *  R WIN  *                                                                                                                                *
             *                                                                                                                                            ***************************************************                                                                                                                                *
             *                                                                                                                                                                                                                                                                                                                               *
             *********************************************************************************************************************************************************************************************************************************************************************************************************************************/
            bindings = <
                                                                                                                            &kp GRAVE     &none &kp F1 &kp F2 &kp F3 &kp F4     &kp F5 &kp F6 &kp F7 &kp F8 &kp F8     &kp F9 &kp F10 &kp F11 &kp F12 &kp F13
                                                                                                        
                                                                                                                                                                                                                            &bootloader &bt BT_NXT
                &kp KP_NLCK &kp KP_SLASH &kp KP_MULTIPLY &kp KP_MINUS                                                       &kp ESC &kp N1  &kp N2  &kp N3  &kp N4  &kp N5  &kp N6  &kp N7  &kp N8  &kp N9  &kp N0  &kp MINUS  &kp EQUAL   &kp BSPC  &kp C_PP                         &kp KP_NLCK &kp KP_SLASH &kp KP_MULTIPLY &kp KP_MINUS
                &kp KP_N7   &kp KP_N8    &kp KP_N9       &kp KP_MINUS    &kp INS   &kp HOME &kp PG_UP                       &kp TAB     &kp Q   &kp W   &kp E   &kp R   &kp T   &kp Y   &kp U   &kp I   &kp O   &kp P   &kp LBKT &kp RBKT   &kp BSLH  &kp DEL                         &kp KP_N7   &kp KP_N8    &kp KP_N9       &kp KP_MINUS
                &kp KP_N4   &kp KP_N5    &kp KP_N6       &kp KP_PLUS     &kp DEL   &kp END  &kp PG_DN                       &kp CAPS      &kp A   &kp S   &kp D   &kp F   &kp G   &kp H   &kp J   &kp K   &kp L  &kp SEMI &kp APOS &kp NUHS &kp ENTER                                 &kp KP_N4   &kp KP_N5    &kp KP_N6       &kp KP_PLUS
                &kp KP_N1   &kp KP_N2    &kp KP_N3       &kp KP_ENTER              &kp UP                                   &kp LSHFT &kp BSLH &kp Z  &kp X   &kp C   &kp V   &kp B   &kp N   &kp M   &kp COMMA &kp DOT &kp FSLH    &kp RSHFT  &kp UP                                 &kp KP_N1   &kp KP_N2    &kp KP_N3       &kp KP_ENTER
                &kp KP_N0   &kp KP_N0    &kp KP_DOT      &kp KP_ENTER    &kp LEFT  &kp DOWN &kp RIGHT                       &kp LCTRL &kp LWIN  &kp LALT  &kp SPACE  &kp SPACE  &kp SPACE         &kp RWIN  &kp RALT  &mo 1       &kp LEFT &kp DOWN &kp RIGHT                         &kp KP_N0   &kp KP_N0    &kp KP_DOT      &kp KP_ENTER

                // unused virtual keys (no mounting points / footprints / traces on board)
                &none &none &none &none &none &none &none &none &none &none &none
            >;

            sensor-bindings = <&inc_dec_kp C_VOL_UP C_VOL_DN &inc_dec_kp C_VOL_UP C_VOL_DN &inc_dec_kp C_VOL_UP C_VOL_DN &inc_dec_kp C_VOL_UP C_VOL_DN &inc_dec_kp C_VOL_UP C_VOL_DN &inc_dec_kp C_VOL_UP C_VOL_DN>;
        };

        fn_layer {
            bindings = <
                                                                                                                            &kp ESC      &trans &trans &trans &trans &trans      &trans &trans &trans &trans &trans      &trans &trans &trans &trans &trans
                                                                                                        
                                                                                                                                                                                                                            &trans      &bt BT_CLR
                &trans      &trans       &trans          &trans                                                             &kp GRAVE &kp F1  &kp F2  &kp F3  &kp F4  &kp F5  &kp F6  &kp F7  &kp F8  &kp F9  &kp F10 &kp F11    &kp F12     &kp F13   &trans                                                                           &trans      &trans       &trans          &trans
                &trans      &trans       &trans          &trans          &trans    &trans   &trans                          &trans &rgb_ug RGB_TOG &rgb_ug RGB_HUD &rgb_ug RGB_HUI &rgb_ug RGB_SAD &rgb_ug RGB_SAI &rgb_ug RGB_BRD &rgb_ug RGB_BRI &rgb_ug RGB_SPD &rgb_ug RGB_SPI &rgb_ug RGB_EFF &rgb_ug RGB_EFR &trans &trans &trans &trans      &trans       &trans          &trans
                &trans      &trans       &trans          &trans          &trans    &trans   &trans                          &trans        &trans  &trans  &trans  &trans  &trans  &trans  &trans  &trans  &trans &trans   &trans   &trans   &trans                                                                                      &trans      &trans       &trans          &trans
                &trans      &trans       &trans          &trans                    &trans                                   &trans    &trans   &trans &trans  &trans  &trans  &trans  &trans  &trans  &trans    &trans  &trans      &trans     &trans                                                                                   &trans      &trans       &trans          &trans
                &trans      &trans       &trans          &trans          &trans    &trans   &trans                          &trans   &trans     &trans    &trans     &trans     &trans            &trans    &trans    &trans      &trans  &trans    &trans                                                                              &trans      &trans       &trans          &trans

                // unused virtual keys (no mounting points / footprints / traces on board)
                &none &none &none &none &none &none &none &none &none &none &none
            >;

            sensor-bindings = <&inc_dec_kp C_VOL_UP C_VOL_DN &inc_dec_kp C_VOL_UP C_VOL_DN &inc_dec_kp C_VOL_UP C_VOL_DN &inc_dec_kp C_VOL_UP C_VOL_DN &inc_dec_kp C_VOL_UP C_VOL_DN &inc_dec_kp C_VOL_UP C_VOL_DN>;
        };

        // due to a hardware layout limitations, if you want to have a flipped numpad layout, you need to use this binding
        #elif defined(FLIPPED_NUMPAD)
        default_layer {
            /*********************************************************************************************************************************************************************************************************************************************************************************************************************************
             * FLIPPED NUMPAD LAYOUT                                                                                                                                                                                                                                                                                                         *
             * NOTE 1: all the options in the keymap graphic show below are available purely in hardware, with no need to change the keymap (* with some exceptions), just solder the switches to their corresponding mounting point                                                                                                         *
             * NOTE 2: the character / keycode in the middle of the key is the normal binding when pressing it down, the one on the top is for when you hold "SHIFT", and the one on the bottom is when you hold "FN"                                                                                                                        *
             *                                                                                                                                                                                                                                                                                                                               *
             *                                                                                                              *********               *********               *********               *********               *********               *********                                                                                *
             *                                                                                                              * ROTARY*               * ROTARY*               * ROTARY*               * ROTARY*               * ROTARY*               * ROTARY*                                                                                *
             *                                                                                                              *ENCODER*               *ENCODER*               *ENCODER*               *ENCODER*               *ENCODER*               *ENCODER*                                                                                *
             *                                                                                                              *********               *********               *********               *********               *********               *********                                                                                *
             *                                                                                                                                                                                                                                                                                                                               *
             *                                                                                                              *********   *********************************   *********************************   *********************************   *********                                                                                *
             *                                                                                                              *   ~   *   *       *       *       *       *   *       *       *       *       *   *       *       *       *       *   *       *                                                                                *
             *                                                                                                              *   `   *   *  F1   *  F2   *  F3   *  F4   *   *  F5   *  F5   *  F6   *  F7   *   *  F9   *   F9  *  F10  *  F11  *   *  F12  *                                                                                *
             *                                                                                                              ***ESC***   *********************************   *********************************   *********************************   *********                                                                                *
             *                                                                                                               _______         _______________________________         _______________________________         _______________________________                                                                                 *
             *                                                                                                              |   ~   |       |       |       |       |       |       |       |       |       |       |       |       |       |       |       |                                                                                *
             *                                                                                                              |   `   |       |  F1   |  F2   |  F3   |  F4   |       |  F5   |  F6   |  F7   |  F8   |       |  F9   |  F10  |  F11  |  F12  |                                                                                *
             *                                                                                                              |__ESC__|       |_______|_______|_______|_______|       |_______|_______|_______|_______|       |_______|_______|_______|_______|                                                                                *
             *                                                                                                                                                                                                                                                                                                                               *
             *                                                                                                                                                                                                                      *************************                                                                                *
             *                                                                                                                                                                                                                      *   | 1U*BACK 1U* ROTARY*                                                                                *
             *            *********************************                                                                                                                                                                         *   \   *SPACE  *ENCODER*                                   *********************************            *
             *            * ROTARY* ROTARY* ROTARY* ROTARY*                                                                                                                                                                         *************************                                   * ROTARY* ROTARY* ROTARY* ROTARY*            *
             *            *ENCODER*ENCODER*ENCODER*ENCODER*                                                                                                                                                                          _______________________                                    *ENCODER*ENCODER*ENCODER*ENCODER*            *
             *            *********************************                                                                                                                                                                         | FLASH |BT_NEXT| POWER |                                   *********************************            *
             *             _______________________________                                                                   _______________________________________________________________________________________________________|_______|BT_CLR_|_______|                                    _______________________________             *
             *            |       |       |       |  NUM  |                                                                 |       |   !   |   @   |   #   |   $   |   %   |   ^   |   &   |   *   |   (   |   )   |   _   |   +   |               |       |                                   |       |       |       |  NUM  |            *
             *            |   -   |   *   |   /   |  LOCK |                                                                 |  ESC  |   1   |   2   |   3   |   4   |   5   |   6   |   7   |   8   |   9   |   0   |   -   |   =   |   BACKSPACE   |  PLAY |                                   |   -   |   *   |   /   |  LOCK |            *
             *  ********* |_______|_______|_______|_______| *********      _______________________                          |___`___|___F1__|___F2__|___F3__|___F4__|___F5__|___F6__|___F7__|___F8__|___F9__|__F10__|__F11__|__F12__|______F13______|_______|       *************     ********* |_______|_______|_______|_______| *********  *
             *  *     1U* |       |       |       |       | *     2U*     |       |       |       |                         |           |       |       |       |       |       |       |       |       |       |       |   {   |   }   |     |     |       |       *        ISO*     *     1U* |       |       |       |       | *     2U*  *
             *  *   -   * |       |   7   |   8   |   9   | *       *     |  INS  |  HOME | PG UP |                         |    TAB    |   Q   |   W   |   E   |   R   |   T   |   Y   |   U   |   I   |   O   |   P   |   [   |   ]   |     \     |  DEL  |       *           *     *   -   * |       |   7   |   8   |   9   | *       *  *
             *  ********* |   +   |_______|_______|_______| *   6   *     |_______|_______|_______|         *************** |___________|RGB_TOG|RGB_HUI|RGB_HUD|RGB_SAI|RGB_SAD|RGB_BRI|RGB_BRD|RGB_SPI|RGB_SPD|RGB_EFF|RGB_EFR|_______|___________|_______| *********  ENTER  *     ********* |   +   |_______|_______|_______| *   6   *  *
             *  *     1U* |       |       |       |       | *       *     |       |       |       |         *STEPPED 1.75U* |             |       |       |       |       |       |       |       |       |       |   :   |   "   |                 |       | *   | 1U*         *     *     1U* |       |       |       |       | *       *  *
             *  *   +   * |       |   4   |   5   |   6   | *       *     |  DEL  |  END  | PG DN |         *CAPS LOCK    * |  CAPS LOCK  |   A   |   S   |   D   |   F   |   G   |   H   |   J   |   K   |   L   |   ;   |   '   |      ENTER      |       | *   \   *         *     *   +   * |       |   4   |   5   |   6   | *       *  *
             *  ********* |_______|_______|_______|_______| *********     |_______|_______|_______|     ******************* |_____________|_______|_______|_______|_______|_______|_______|_______|_______|_______|_______|_______|_________________|DISPLAY| *******************     ********* |_______|_______|_______|_______| *********  *
             *  *     1U* |       |       |       |       | *     2U*             |       |             *    1.25U*   | 1U* |                 |       |       |       |       |       |       |       |   <   |   >   |   ?   |             |       |       |                         *     1U* |       |       |       |       | *     2U*  *
             *  * ENTER * |       |   1   |   2   |   3   | *       *             |  UP   |             * L SHIFT *   \   * |     L SHIFT     |   Z   |   X   |   C   |   V   |   B   |   N   |   M   |   ,   |   .   |   /   |   R SHIFT   |  UP   |       |                         * ENTER * |       |   1   |   2   |   3   | *       *  *
             *  ********* | ENTER |_______|_______|_______| *   0   *      _______|_______|_______      ******************* |_________________|_______|_______|_______|_______|_______|_______|_______|_______|_______|_______|_____________|_______|_______|                         ********* | ENTER |_______|_______|_______| *   0   *  *
             *  *     1U* |       |       |               | *       *     |       |       |       |                         |         |         |         |                                                 |         |         |   |       |       |       |                         *     1U* |       |       |               | *       *  *
             *  * ENTER * |       |   .   |       0       | *       *     |  LEFT |  DOWN |   0   |                         |  L CTRL |  L WIN  |  L ALT  |                                                 |  R ALT  |   FN    |   |  LEFT |  DOWN | RIGHT |                         * ENTER * |       |   .   |       0       | *       *  *
             *  ********* |_______|_______|_______________| *********     |_______|_______|_______|                         |_________|_________|_________|_________________________________________________|_________|_________|   |_______|_______|_______|                         ********* |_______|_______|_______________| *********  *
             *                                                                                                                                                                                                                                                                                                                               *
             *            *********************************                                                                                                                                                                   ***********************                                           *********************************            *
             *            *             2U*     1U*     1U*                                                                                                                                                                   *                2.75U*                                           *             2U*     1U*     1U*            *
             *            *      LEFT     *   0   *   0   *                                                                                                                                                                   *       R SHIFT       *                                           *      LEFT     *   0   *   0   *            *
             *            *********************************                                                                 *************************************************************************************************************************                                           *********************************            *
             *                                                                                                              *       1.5U*     1U*       1.5U*                                                     7U*       1.5U*     1U*       1.5U*                                                                                        *
             *                                                                                                              *  L CTRL   * L WIN *   L ALT   *                                                       *   R ALT   * R WIN *  R CTRL   *                                                                                        *
             *                                                                                                              *************************************************************************************************************************                                                                                        *
             *                                                                                                                                                                                                                                                                                                                               *
             *                                                                                                                                            ***************************************************                                                                                                                                *
             *                                                                                                                                            *                2.75U*            2.25U*    1.25U*                                                                                                                                *
             *                                                                                                                                            *                     *                 *  R WIN  *                                                                                                                                *
             *                                                                                                                                            ***************************************************                                                                                                                                *
             *                                                                                                                                                                                                                                                                                                                               *
             *********************************************************************************************************************************************************************************************************************************************************************************************************************************/
            bindings = <
                                                                                                                            &kp GRAVE     &none &kp F1 &kp F2 &kp F3 &kp F4     &kp F5 &kp F5 &kp F6 &kp F7 &kp F8     &kp F9 &kp F9 &kp F10 &kp F11 &kp F12
                                                                                                        
                                                                                                                                                                                                                            &bootloader &bt BT_NXT
                &kp KP_MINUS &kp KP_MULTIPLY &kp KP_SLASH &kp KP_NLCK                                                       &kp ESC &kp N1  &kp N2  &kp N3  &kp N4  &kp N5  &kp N6  &kp N7  &kp N8  &kp N9  &kp N0  &kp MINUS  &kp EQUAL   &kp BSPC  &kp C_PP                         &kp KP_MINUS &kp KP_MULTIPLY &kp KP_SLASH &kp KP_NLCK
                &kp KP_MINUS &kp KP_N7       &kp KP_N8    &kp KP_N9      &kp INS   &kp HOME &kp PG_UP                       &kp TAB     &kp Q   &kp W   &kp E   &kp R   &kp T   &kp Y   &kp U   &kp I   &kp O   &kp P   &kp LBKT &kp RBKT   &kp BSLH  &kp DEL                         &kp KP_MINUS &kp KP_N7       &kp KP_N8    &kp KP_N9
                &kp KP_PLUS  &kp KP_N4       &kp KP_N5    &kp KP_N6      &kp DEL   &kp END  &kp PG_DN                       &kp CAPS      &kp A   &kp S   &kp D   &kp F   &kp G   &kp H   &kp J   &kp K   &kp L  &kp SEMI &kp APOS &kp NUHS &kp ENTER                                 &kp KP_PLUS  &kp KP_N4       &kp KP_N5    &kp KP_N6
                &kp KP_ENTER &kp KP_N1       &kp KP_N2    &kp KP_N3                &kp UP                                   &kp LSHFT &kp BSLH &kp Z  &kp X   &kp C   &kp V   &kp B   &kp N   &kp M   &kp COMMA &kp DOT &kp FSLH    &kp RSHFT  &kp UP                                 &kp KP_ENTER &kp KP_N1       &kp KP_N2    &kp KP_N3
                &kp KP_ENTER &kp KP_DOT      &kp KP_N0    &kp KP_N0      &kp LEFT  &kp DOWN &kp KP_N0                       &kp LCTRL &kp LWIN  &kp LALT  &kp SPACE  &kp SPACE  &kp SPACE         &kp RWIN  &kp RALT  &mo 1       &kp LEFT &kp DOWN &kp RIGHT                         &kp KP_ENTER &kp KP_DOT      &kp KP_N0    &kp KP_N0

                // unused virtual keys (no mounting points / footprints / traces on board)
                &none &none &none &none &none &none &none &none &none &none &none
            >;

            sensor-bindings = <&inc_dec_kp C_VOL_UP C_VOL_DN &inc_dec_kp C_VOL_UP C_VOL_DN &inc_dec_kp C_VOL_UP C_VOL_DN &inc_dec_kp C_VOL_UP C_VOL_DN &inc_dec_kp C_VOL_UP C_VOL_DN &inc_dec_kp C_VOL_UP C_VOL_DN>;
        };

        fn_layer {
            bindings = <
                                                                                                                            &kp ESC      &trans &trans &trans &trans &trans      &trans &trans &trans &trans &trans      &trans &trans &trans &trans &trans
                                                                                                        
                                                                                                                                                                                                                            &trans      &bt BT_CLR
                &trans      &trans       &trans          &trans                                                             &kp GRAVE &kp F1  &kp F2  &kp F3  &kp F4  &kp F5  &kp F6  &kp F7  &kp F8  &kp F9  &kp F10 &kp F11    &kp F12     &kp F13   &trans                                                                           &trans      &trans       &trans          &trans
                &trans      &trans       &trans          &trans          &trans    &trans   &trans                          &trans &rgb_ug RGB_TOG &rgb_ug RGB_HUD &rgb_ug RGB_HUI &rgb_ug RGB_SAD &rgb_ug RGB_SAI &rgb_ug RGB_BRD &rgb_ug RGB_BRI &rgb_ug RGB_SPD &rgb_ug RGB_SPI &rgb_ug RGB_EFF &rgb_ug RGB_EFR &trans &trans &trans &trans      &trans       &trans          &trans
                &trans      &trans       &trans          &trans          &trans    &trans   &trans                          &trans        &trans  &trans  &trans  &trans  &trans  &trans  &trans  &trans  &trans &trans   &trans   &trans   &trans                                                                                      &trans      &trans       &trans          &trans
                &trans      &trans       &trans          &trans                    &trans                                   &trans    &trans   &trans &trans  &trans  &trans  &trans  &trans  &trans  &trans    &trans  &trans      &trans     &trans                                                                                   &trans      &trans       &trans          &trans
                &trans      &trans       &trans          &trans          &trans    &trans   &trans                          &trans   &trans     &trans    &trans     &trans     &trans            &trans    &trans    &trans      &trans  &trans    &trans                                                                              &trans      &trans       &trans          &trans

                // unused virtual keys (no mounting points / footprints / traces on board)
                &none &none &none &none &none &none &none &none &none &none &none
            >;

            sensor-bindings = <&inc_dec_kp C_VOL_UP C_VOL_DN &inc_dec_kp C_VOL_UP C_VOL_DN &inc_dec_kp C_VOL_UP C_VOL_DN &inc_dec_kp C_VOL_UP C_VOL_DN &inc_dec_kp C_VOL_UP C_VOL_DN &inc_dec_kp C_VOL_UP C_VOL_DN>;
        };

        // due to a hardware layout limitations, if you want to have a flipped numpad layout and an F13 layout function row, you need to use this binding
        #elif defined(FLIPPED_NUMPAD_F13)
        default_layer {
            /*********************************************************************************************************************************************************************************************************************************************************************************************************************************
             * FLIPPED NUMPAD LAYOUT                                                                                                                                                                                                                                                                                                         *
             * NOTE 1: all the options in the keymap graphic show below are available purely in hardware, with no need to change the keymap (* with some exceptions), just solder the switches to their corresponding mounting point                                                                                                         *
             * NOTE 2: the character / keycode in the middle of the key is the normal binding when pressing it down, the one on the top is for when you hold "SHIFT", and the one on the bottom is when you hold "FN"                                                                                                                        *
             *                                                                                                                                                                                                                                                                                                                               *
             *                                                                                                              *********               *********               *********               *********               *********               *********                                                                                *
             *                                                                                                              * ROTARY*               * ROTARY*               * ROTARY*               * ROTARY*               * ROTARY*               * ROTARY*                                                                                *
             *                                                                                                              *ENCODER*               *ENCODER*               *ENCODER*               *ENCODER*               *ENCODER*               *ENCODER*                                                                                *
             *                                                                                                              *********               *********               *********               *********               *********               *********                                                                                *
             *                                                                                                                                                                                                                                                                                                                               *
             *                                                                                                              *********   *********************************   *********************************   *********************************   *********                                                                                *
             *                                                                                                              *   ~   *   *       *       *       *       *   *       *       *       *       *   *       *       *       *       *   *       *                                                                                *
             *                                                                                                              *   `   *   *  F1   *  F2   *  F3   *  F4   *   *  F5   *  F6   *  F7   *  F8   *   *  F9   *  F10  *  F11  *  F12  *   *  F13  *                                                                                *
             *                                                                                                              ***ESC***   *********************************   *********************************   *********************************   *********                                                                                *
             *                                                                                                               _______         _______________________________         _______________________________         _______________________________                                                                                 *
             *                                                                                                              |   ~   |       |       |       |       |       |       |       |       |       |       |       |       |       |       |       |                                                                                *
             *                                                                                                              |   `   |       |  F1   |  F2   |  F3   |  F4   |       |  F6   |  F7   |  F8   |  F8   |       |  F10  |  F11  |  F12  |  F13  |                                                                                *
             *                                                                                                              |__ESC__|       |_______|_______|_______|_______|       |_______|_______|_______|_______|       |_______|_______|_______|_______|                                                                                *
             *                                                                                                                                                                                                                                                                                                                               *
             *                                                                                                                                                                                                                      *************************                                                                                *
             *                                                                                                                                                                                                                      *   | 1U*BACK 1U* ROTARY*                                                                                *
             *            *********************************                                                                                                                                                                         *   \   *SPACE  *ENCODER*                                   *********************************            *
             *            * ROTARY* ROTARY* ROTARY* ROTARY*                                                                                                                                                                         *************************                                   * ROTARY* ROTARY* ROTARY* ROTARY*            *
             *            *ENCODER*ENCODER*ENCODER*ENCODER*                                                                                                                                                                          _______________________                                    *ENCODER*ENCODER*ENCODER*ENCODER*            *
             *            *********************************                                                                                                                                                                         | FLASH |BT_NEXT| POWER |                                   *********************************            *
             *             _______________________________                                                                   _______________________________________________________________________________________________________|_______|BT_CLR_|_______|                                    _______________________________             *
             *            |       |       |       |  NUM  |                                                                 |       |   !   |   @   |   #   |   $   |   %   |   ^   |   &   |   *   |   (   |   )   |   _   |   +   |               |       |                                   |       |       |       |  NUM  |            *
             *            |   -   |   *   |   /   |  LOCK |                                                                 |  ESC  |   1   |   2   |   3   |   4   |   5   |   6   |   7   |   8   |   9   |   0   |   -   |   =   |   BACKSPACE   |  PLAY |                                   |   -   |   *   |   /   |  LOCK |            *
             *  ********* |_______|_______|_______|_______| *********      _______________________                          |___`___|___F1__|___F2__|___F3__|___F4__|___F5__|___F6__|___F7__|___F8__|___F9__|__F10__|__F11__|__F12__|______F13______|_______|       *************     ********* |_______|_______|_______|_______| *********  *
             *  *     1U* |       |       |       |       | *     2U*     |       |       |       |                         |           |       |       |       |       |       |       |       |       |       |       |   {   |   }   |     |     |       |       *        ISO*     *     1U* |       |       |       |       | *     2U*  *
             *  *   -   * |       |   7   |   8   |   9   | *       *     |  INS  |  HOME | PG UP |                         |    TAB    |   Q   |   W   |   E   |   R   |   T   |   Y   |   U   |   I   |   O   |   P   |   [   |   ]   |     \     |  DEL  |       *           *     *   -   * |       |   7   |   8   |   9   | *       *  *
             *  ********* |   +   |_______|_______|_______| *   6   *     |_______|_______|_______|         *************** |___________|RGB_TOG|RGB_HUI|RGB_HUD|RGB_SAI|RGB_SAD|RGB_BRI|RGB_BRD|RGB_SPI|RGB_SPD|RGB_EFF|RGB_EFR|_______|___________|_______| *********  ENTER  *     ********* |   +   |_______|_______|_______| *   6   *  *
             *  *     1U* |       |       |       |       | *       *     |       |       |       |         *STEPPED 1.75U* |             |       |       |       |       |       |       |       |       |       |   :   |   "   |                 |       | *   | 1U*         *     *     1U* |       |       |       |       | *       *  *
             *  *   +   * |       |   4   |   5   |   6   | *       *     |  DEL  |  END  | PG DN |         *CAPS LOCK    * |  CAPS LOCK  |   A   |   S   |   D   |   F   |   G   |   H   |   J   |   K   |   L   |   ;   |   '   |      ENTER      |       | *   \   *         *     *   +   * |       |   4   |   5   |   6   | *       *  *
             *  ********* |_______|_______|_______|_______| *********     |_______|_______|_______|     ******************* |_____________|_______|_______|_______|_______|_______|_______|_______|_______|_______|_______|_______|_________________|DISPLAY| *******************     ********* |_______|_______|_______|_______| *********  *
             *  *     1U* |       |       |       |       | *     2U*             |       |             *    1.25U*   | 1U* |                 |       |       |       |       |       |       |       |   <   |   >   |   ?   |             |       |       |                         *     1U* |       |       |       |       | *     2U*  *
             *  * ENTER * |       |   1   |   2   |   3   | *       *             |  UP   |             * L SHIFT *   \   * |     L SHIFT     |   Z   |   X   |   C   |   V   |   B   |   N   |   M   |   ,   |   .   |   /   |   R SHIFT   |  UP   |       |                         * ENTER * |       |   1   |   2   |   3   | *       *  *
             *  ********* | ENTER |_______|_______|_______| *   0   *      _______|_______|_______      ******************* |_________________|_______|_______|_______|_______|_______|_______|_______|_______|_______|_______|_____________|_______|_______|                         ********* | ENTER |_______|_______|_______| *   0   *  *
             *  *     1U* |       |       |               | *       *     |       |       |       |                         |         |         |         |                                                 |         |         |   |       |       |       |                         *     1U* |       |       |               | *       *  *
             *  * ENTER * |       |   .   |       0       | *       *     |  LEFT |  DOWN |   0   |                         |  L CTRL |  L WIN  |  L ALT  |                                                 |  R ALT  |   FN    |   |  LEFT |  DOWN | RIGHT |                         * ENTER * |       |   .   |       0       | *       *  *
             *  ********* |_______|_______|_______________| *********     |_______|_______|_______|                         |_________|_________|_________|_________________________________________________|_________|_________|   |_______|_______|_______|                         ********* |_______|_______|_______________| *********  *
             *                                                                                                                                                                                                                                                                                                                               *
             *            *********************************                                                                                                                                                                   ***********************                                           *********************************            *
             *            *             2U*     1U*     1U*                                                                                                                                                                   *                2.75U*                                           *             2U*     1U*     1U*            *
             *            *      LEFT     *   0   *   0   *                                                                                                                                                                   *       R SHIFT       *                                           *      LEFT     *   0   *   0   *            *
             *            *********************************                                                                 *************************************************************************************************************************                                           *********************************            *
             *                                                                                                              *       1.5U*     1U*       1.5U*                                                     7U*       1.5U*     1U*       1.5U*                                                                                        *
             *                                                                                                              *  L CTRL   * L WIN *   L ALT   *                                                       *   R ALT   * R WIN *  R CTRL   *                                                                                        *
             *                                                                                                              *************************************************************************************************************************                                                                                        *
             *                                                                                                                                                                                                                                                                                                                               *
             *                                                                                                                                            ***************************************************                                                                                                                                *
             *                                                                                                                                            *                2.75U*            2.25U*    1.25U*                                                                                                                                *
             *                                                                                                                                            *                     *                 *  R WIN  *                                                                                                                                *
             *                                                                                                                                            ***************************************************                                                                                                                                *
             *                                                                                                                                                                                                                                                                                                                               *
             *********************************************************************************************************************************************************************************************************************************************************************************************************************************/
            bindings = <
                                                                                                                            &kp GRAVE     &none &kp F1 &kp F2 &kp F3 &kp F4     &kp F5 &kp F6 &kp F7 &kp F8 &kp F8     &kp F9 &kp F10 &kp F11 &kp F12 &kp F13
                                                                                                        
                                                                                                                                                                                                                            &bootloader &bt BT_NXT
                &kp KP_MINUS &kp KP_MULTIPLY &kp KP_SLASH &kp KP_NLCK                                                       &kp ESC &kp N1  &kp N2  &kp N3  &kp N4  &kp N5  &kp N6  &kp N7  &kp N8  &kp N9  &kp N0  &kp MINUS  &kp EQUAL   &kp BSPC  &kp C_PP                         &kp KP_MINUS &kp KP_MULTIPLY &kp KP_SLASH &kp KP_NLCK
                &kp KP_MINUS &kp KP_N7       &kp KP_N8    &kp KP_N9      &kp INS   &kp HOME &kp PG_UP                       &kp TAB     &kp Q   &kp W   &kp E   &kp R   &kp T   &kp Y   &kp U   &kp I   &kp O   &kp P   &kp LBKT &kp RBKT   &kp BSLH  &kp DEL                         &kp KP_MINUS &kp KP_N7       &kp KP_N8    &kp KP_N9
                &kp KP_PLUS  &kp KP_N4       &kp KP_N5    &kp KP_N6      &kp DEL   &kp END  &kp PG_DN                       &kp CAPS      &kp A   &kp S   &kp D   &kp F   &kp G   &kp H   &kp J   &kp K   &kp L  &kp SEMI &kp APOS &kp NUHS &kp ENTER                                 &kp KP_PLUS  &kp KP_N4       &kp KP_N5    &kp KP_N6
                &kp KP_ENTER &kp KP_N1       &kp KP_N2    &kp KP_N3                &kp UP                                   &kp LSHFT &kp BSLH &kp Z  &kp X   &kp C   &kp V   &kp B   &kp N   &kp M   &kp COMMA &kp DOT &kp FSLH    &kp RSHFT  &kp UP                                 &kp KP_ENTER &kp KP_N1       &kp KP_N2    &kp KP_N3
                &kp KP_ENTER &kp KP_DOT      &kp KP_N0    &kp KP_N0      &kp LEFT  &kp DOWN &kp KP_N0                       &kp LCTRL &kp LWIN  &kp LALT  &kp SPACE  &kp SPACE  &kp SPACE         &kp RWIN  &kp RALT  &mo 1       &kp LEFT &kp DOWN &kp RIGHT                         &kp KP_ENTER &kp KP_DOT      &kp KP_N0    &kp KP_N0

                // unused virtual keys (no mounting points / footprints / traces on board)
                &none &none &none &none &none &none &none &none &none &none &none
            >;

            sensor-bindings = <&inc_dec_kp C_VOL_UP C_VOL_DN &inc_dec_kp C_VOL_UP C_VOL_DN &inc_dec_kp C_VOL_UP C_VOL_DN &inc_dec_kp C_VOL_UP C_VOL_DN &inc_dec_kp C_VOL_UP C_VOL_DN &inc_dec_kp C_VOL_UP C_VOL_DN>;
        };

        fn_layer {
            bindings = <
                                                                                                                            &kp ESC      &trans &trans &trans &trans &trans      &trans &trans &trans &trans &trans      &trans &trans &trans &trans &trans
                                                                                                        
                                                                                                                                                                                                                            &trans      &bt BT_CLR
                &trans      &trans       &trans          &trans                                                             &kp GRAVE &kp F1  &kp F2  &kp F3  &kp F4  &kp F5  &kp F6  &kp F7  &kp F8  &kp F9  &kp F10 &kp F11    &kp F12     &kp F13   &trans                                                                           &trans      &trans       &trans          &trans
                &trans      &trans       &trans          &trans          &trans    &trans   &trans                          &trans &rgb_ug RGB_TOG &rgb_ug RGB_HUD &rgb_ug RGB_HUI &rgb_ug RGB_SAD &rgb_ug RGB_SAI &rgb_ug RGB_BRD &rgb_ug RGB_BRI &rgb_ug RGB_SPD &rgb_ug RGB_SPI &rgb_ug RGB_EFF &rgb_ug RGB_EFR &trans &trans &trans &trans      &trans       &trans          &trans
                &trans      &trans       &trans          &trans          &trans    &trans   &trans                          &trans        &trans  &trans  &trans  &trans  &trans  &trans  &trans  &trans  &trans &trans   &trans   &trans   &trans                                                                                      &trans      &trans       &trans          &trans
                &trans      &trans       &trans          &trans                    &trans                                   &trans    &trans   &trans &trans  &trans  &trans  &trans  &trans  &trans  &trans    &trans  &trans      &trans     &trans                                                                                   &trans      &trans       &trans          &trans
                &trans      &trans       &trans          &trans          &trans    &trans   &trans                          &trans   &trans     &trans    &trans     &trans     &trans            &trans    &trans    &trans      &trans  &trans    &trans                                                                              &trans      &trans       &trans          &trans

                // unused virtual keys (no mounting points / footprints / traces on board)
                &none &none &none &none &none &none &none &none &none &none &none
            >;

            sensor-bindings = <&inc_dec_kp C_VOL_UP C_VOL_DN &inc_dec_kp C_VOL_UP C_VOL_DN &inc_dec_kp C_VOL_UP C_VOL_DN &inc_dec_kp C_VOL_UP C_VOL_DN &inc_dec_kp C_VOL_UP C_VOL_DN &inc_dec_kp C_VOL_UP C_VOL_DN>;
        };
        #endif
    };
};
